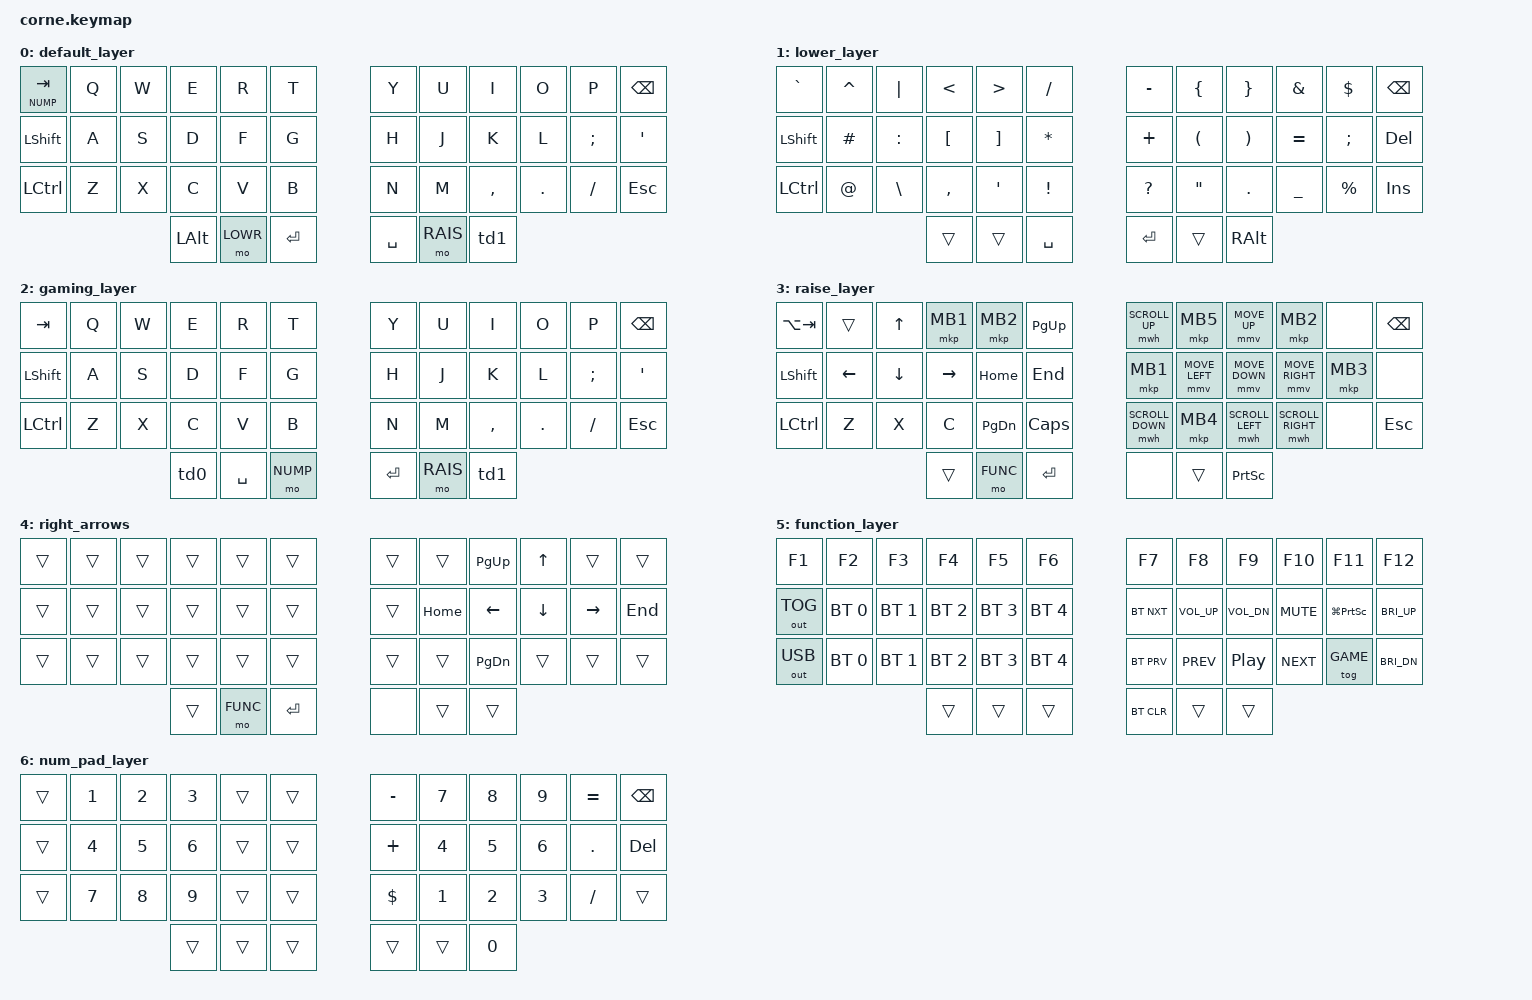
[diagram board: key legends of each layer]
/*
 * Copyright (c) 2020 The ZMK Contributors
 *
 * SPDX-License-Identifier: MIT
 */

#include <behaviors.dtsi>
#include <dt-bindings/zmk/keys.h>
#include <dt-bindings/zmk/bt.h>
#include <dt-bindings/zmk/mouse.h>
#include <dt-bindings/zmk/outputs.h>

#define U_MOUSE_MOVE_MAX 2000                     /* <--- New max speed setting (default: 600) */
#undef MOVE_UP
#undef MOVE_DOWN
#undef MOVE_LEFT
#undef MOVE_RIGHT
#define MOVE_UP MOVE_VERT(-U_MOUSE_MOVE_MAX)
#define MOVE_DOWN MOVE_VERT(U_MOUSE_MOVE_MAX)
#define MOVE_LEFT MOVE_HOR(-U_MOUSE_MOVE_MAX)
#define MOVE_RIGHT MOVE_HOR(U_MOUSE_MOVE_MAX)

&mmv {
	time-to-max-speed-ms = <1000>;             /* <--- How long time until max speed is reached (default: 500) */
};

#define U_MOUSE_SCROLL_MAX 50                    /* <--- New max speed setting (default: 10) */

#undef SCROLL_UP
#undef SCROLL_DOWN
#undef SCROLL_LEFT
#undef SCROLL_RIGHT
#define SCROLL_UP SCROLL_VERT(U_MOUSE_SCROLL_MAX)
#define SCROLL_DOWN SCROLL_VERT(-U_MOUSE_SCROLL_MAX)
#define SCROLL_LEFT SCROLL_HOR(-U_MOUSE_SCROLL_MAX)
#define SCROLL_RIGHT SCROLL_HOR(U_MOUSE_SCROLL_MAX)

#define WORD 0
#define LOWR 1
#define GAME 2
#define RAIS 3
#define RARR 4
#define FUNC 5
#define NUMP 6

&mwh {
  time-to-max-speed-ms = <1000>;                 /* <--- How long time until max speed is reached */
  acceleration-exponent=<1>;
};

/ {
        behaviors {
            td0: tap_dance_0{
                compatible = "zmk,behavior-tap-dance";
                label = "TAP_DANCE_0"; // Add the label property with a value
                #binding-cells = <0>;
                tapping-term-ms = <200>;
                bindings = <&kp LALT>,<&sl NUMP>;
            };
            td1: tap_dance_1{
                compatible = "zmk,behavior-tap-dance";
                label= "TAP_DANCE_1";
                #binding-cells = <0>;
                tapping-term-ms = <200>;
                bindings = <&mo RARR>,<&kp LGUI>;
            };
        };

        keymap {
                compatible = "zmk,keymap";

                default_layer {
// --------------------------------------------------------------------------------
// |NP-TAB|  Q  |  W  |  E  |  R  |  T  |   |  Y  |  U   |  I  |  O  |  P  | BKSP |
// | SHFT |  A  |  S  |  D  |  F  |  G  |   |  H  |  J   |  K  |  L  |  ;  |  '   |
// | CTRL |  Z  |  X  |  C  |  V  |  B  |   |  N  |  M   |  ,  |  .  |  /  | ESC  |
//                    | GUI | LWR | ENT |   | SPC | RSE  | ALT |
                        bindings = <
   &lt NUMP TAB &kp Q &kp W &kp E &kp R &kp T      &kp Y &kp U  &kp I     &kp O   &kp P    &kp BSPC
   &kp LSHFT    &kp A &kp S &kp D &kp F &kp G      &kp H &kp J  &kp K     &kp L   &kp SEMI &kp SQT
   &kp LCTRL    &kp Z &kp X &kp C &kp V &kp B      &kp N &kp M  &kp COMMA &kp DOT &kp FSLH &kp ESC
                   &kp LALT &mo LOWR &kp RET       &kp SPACE &mo RAIS &td1
                        >;
                };
                lower_layer {
// -------------------------------------------------------------------------------
// |  `   |  ^  | "|" |  <  |  >  |  /  |   |  -  |  {  |  }  |  &  |  $  | BKSP |
// | SHFT |  #  |  :  |  [  |  ]  |  *  |   |  +  |  (  |  )  |  =  |  ;  | DLTE |
// | CTRL |  @  |  \  |  ,  |  '  |  !  |   |  ?  |  "  |  .  |  _  |  %  | INS  |
//                    | GUI |     | SPC |   | ENT |     | ALT |
                        bindings = <
   &kp GRAVE  &kp CARET  &kp PIPE   &kp LT    &kp GT   &kp FSLH          &kp MINUS  &kp LBRC  &kp RBRC   &kp AMPS   &kp DLLR      &kp BSPC
   &kp LSHFT  &kp HASH   &kp COLON  &kp LBKT  &kp RBKT &kp STAR          &kp PLUS   &kp LPAR  &kp RPAR   &kp EQUAL  &kp SEMI      &kp DEL
   &kp LCTRL  &kp AT     &kp BSLH   &kp COMMA &kp SQT  &kp EXCL          &kp QMARK  &kp DQT   &kp DOT    &kp UNDER  &kp PRCNT     &kp INS
                                    &trans    &trans   &kp SPACE         &kp RET    &trans    &kp RALT
                        >;
                };

                gaming_layer {
// --------------------------------------------------------------------------------
// | TAB  |  Q  |  W  |  E  |  R  |  T  |   |  Y  |  U   |  I  |  O  |  P  | BKSP |
// | SHFT |  A  |  S  |  D  |  F  |  G  |   |  H  |  J   |  K  |  L  |  ;  |  '   |
// | CTRL |  Z  |  X  |  C  |  V  |  B  |   |  N  |  M   |  ,  |  .  |  /  | ESC  |
//                    | GUI | #pad| SPC |   | RET | RSE  | ALT |
                        bindings = <
   &kp TAB   &kp Q &kp W &kp E &kp R &kp T       &kp Y   &kp U    &kp I     &kp O   &kp P    &kp BSPC
   &kp LSHFT &kp A &kp S &kp D &kp F &kp G       &kp H   &kp J    &kp K     &kp L   &kp SEMI &kp SQT
   &kp LCTRL &kp Z &kp X &kp C &kp V &kp B       &kp N   &kp M    &kp COMMA &kp DOT &kp FSLH &kp ESC
                         &td0 &kp SPACE &mo NUMP &kp RET &mo RAIS &td1
                        >;
                };

                raise_layer {
// --------------------------------------------------------------------------------------
// |ALTTAB|     | UP   | MB1 | MB2  | PGUP |   | MWUP | MB5 | MUP | MB2 | BUP  | BKSP |
// | SHFT | LFT | DWN  | RGHT| HOME | END  |   | MBT1 | MLT | MDN | MRT | MB3  | NONE |
// | CTRL |  Z  |  X   |  C  | PGDN | CAPS |   | MWDN | MB4 | MWL | MWR | BDWN | ESC  |
//                     | GUI |      | ENTR |   | None |     | SCRN|
                        bindings = <
   &kp LA(TAB) &trans   &kp UP   &mkp MB1  &mkp MB2  &kp PG_UP          &mwh SCROLL_UP   &mkp MB5       &mmv MOVE_UP     &mkp MB2          &none     &kp BSPC
   &kp LSHFT   &kp LEFT &kp DOWN &kp RIGHT &kp HOME  &kp END            &mkp MB1         &mmv MOVE_LEFT &mmv MOVE_DOWN   &mmv MOVE_RIGHT   &mkp MB3  &none
   &kp LCTRL   &kp Z    &kp X    &kp C     &kp PG_DN &kp CAPS           &mwh SCROLL_DOWN &mkp MB4       &mwh SCROLL_LEFT &mwh SCROLL_RIGHT &none     &kp ESC
                                 &trans    &mo FUNC  &kp RET            &none            &trans         &kp PSCRN
                       >;
                };
                
                right_arrows {
// --------------------------------------------------------------------------------------
// |ALTTAB|     | UP   | MB1 | MB2  | END  |   | tran | tran | PGUP |  UP  | tran | tran |
// | SHFT | LFT | DWN  | RGHT| PGUP | HOME |   | tran | Home | LEFT | DOWN | RGHT | END  |
// | CTRL |  Z  |  X   |  C  | PGDN | CAPS |   | tran | tran | PGDN | tran | tran | tran |
//                     | GUI |      | ENTR |   | tran | tran | tran |
                        bindings = <
   &trans &trans &trans &trans &trans &trans           &trans &trans   &kp PG_UP &kp UP   &trans    &trans
   &trans &trans &trans &trans &trans &trans           &trans &kp HOME &kp LEFT  &kp DOWN &kp RIGHT &kp END
   &trans &trans &trans &trans &trans &trans           &trans &trans   &kp PG_DN &trans   &trans    &trans
                        &trans &mo FUNC &kp RET        &none  &trans   &trans
                       >;
                };

                function_layer {
// -------------------------------------------------------------------------------------
// |  F1  | F2  |  F3  |  F4  |  F5  |  F6  |   | F7  | F8  | F9  | F10 | F11  | F12    | 
// | SHFT | LFT | DWN  | RGHT | PGDN | END  |   |  +  | VUP | VDN | MUTE| SCRN | BTPREV |
// | PREV | PP  | NEXT | VUP  | MUTE | VDWN |   |  -  | PRV | CPP | NXT |      |        |
//                     | GUI  |      | SPC  |   | ENT |     |  0  |
                        bindings = <
   &kp F1       &kp F2        &kp F3        &kp F4        &kp F5        &kp F6              &kp F7     &kp F8       &kp F9       &kp F10    &kp F11       &kp F12
   &out OUT_TOG &bt BT_SEL 0  &bt BT_SEL 1  &bt BT_SEL 2  &bt BT_SEL 3  &bt BT_SEL 4        &bt BT_NXT &kp C_VOL_UP &kp C_VOL_DN &kp C_MUTE &kp LG(PSCRN) &kp C_BRI_UP
   &out OUT_USB &bt BT_SEL 0  &bt BT_SEL 1  &bt BT_SEL 2  &bt BT_SEL 3  &bt BT_SEL 4        &bt BT_PRV &kp C_PREV   &kp C_PP     &kp C_NEXT &tog GAME     &kp C_BRI_DN
                                            &trans        &trans        &trans              &bt BT_CLR &trans       &trans
                        >;
                };

                num_pad_layer {
// ---------------------------------------------------------------------------------------------
// | trans | trans | trans | trans | trans | trans |    |  -  |  7  |  8  |  9  |  =   | trans | 
// | trans | trans | trans | trans | trans | trans |    |  +  |  4  |  5  |  6  |  /   | DLTE  |
// | trans | trans | trans | trans | trans | trans |    |  $  |  1  |  2  |  3  |  dot | trans |
//                         | GUI   |       | ENT   |    | SPC |     |  0  |
                        bindings = <
   &trans &kp N1  &kp N2  &kp N3  &trans &trans    &kp MINUS  &kp N7 &kp N8 &kp N9 &kp EQUAL &kp BSPC
   &trans &kp N4  &kp N5  &kp N6  &trans &trans    &kp PLUS   &kp N4 &kp N5 &kp N6 &kp DOT   &kp DEL
   &trans &kp N7  &kp N8  &kp N9  &trans &trans    &kp DLLR   &kp N1 &kp N2 &kp N3 &kp FSLH  &trans
                          &trans  &trans &trans    &trans     &trans &kp NUMBER_0
                        >;
                };
        };

};
